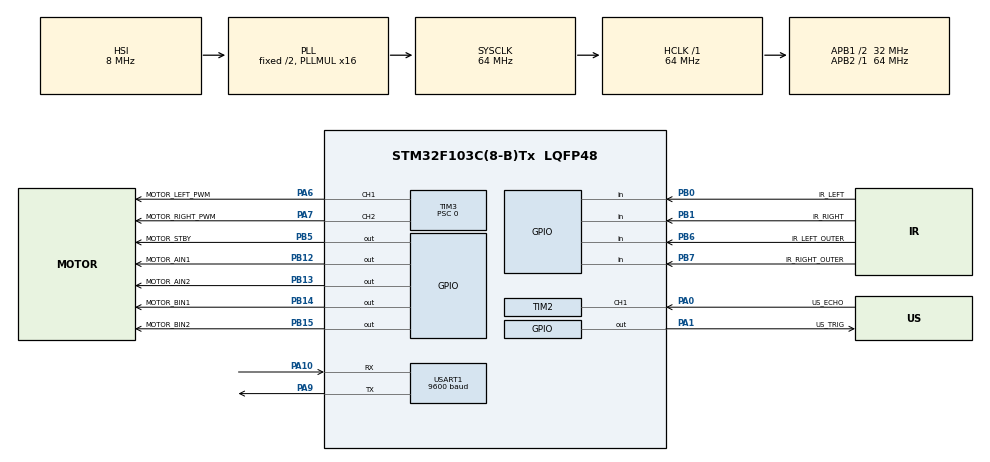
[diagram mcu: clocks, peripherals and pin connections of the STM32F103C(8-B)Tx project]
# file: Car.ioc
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Mcu.Family=STM32F1
Mcu.Name=STM32F103C(8-B)Tx
Mcu.Package=LQFP48
NVIC.PriorityGroup=NVIC_PRIORITYGROUP_4
NVIC.TIM2_IRQn=true\:1\:0\:false\:false\:true\:true\:true\:true
NVIC.USART1_IRQn=true\:2\:0\:false\:false\:true\:true\:true\:true
PA0-WKUP.GPIO_Label=US_ECHO
PA0-WKUP.Signal=S_TIM2_CH1_ETR
PA1.GPIO_Label=US_TRIG
PA1.GPIO_ModeDefaultOutputPP=GPIO_MODE_OUTPUT_PP
PA1.GPIO_PuPd=GPIO_NOPULL
PA1.GPIO_Speed=GPIO_SPEED_FREQ_LOW
PA1.PinState=GPIO_PIN_RESET
PA1.Signal=GPIO_Output
PA10.Mode=Asynchronous
PA10.Signal=USART1_RX
PA13.Mode=Serial_Wire
PA13.Signal=SYS_JTMS-SWDIO
PA14.Mode=Serial_Wire
PA14.Signal=SYS_JTCK-SWCLK
PA6.GPIO_Label=MOTOR_LEFT_PWM
PA6.Signal=S_TIM3_CH1
PA7.GPIO_Label=MOTOR_RIGHT_PWM
PA7.Signal=S_TIM3_CH2
PA9.Mode=Asynchronous
PA9.Signal=USART1_TX
PB0.GPIO_Label=IR_LEFT
PB0.GPIO_PuPd=GPIO_PULLUP
PB0.Signal=GPIO_Input
PB1.GPIO_Label=IR_RIGHT
PB1.GPIO_PuPd=GPIO_PULLUP
PB1.Signal=GPIO_Input
PB12.GPIO_Label=MOTOR_AIN1
PB12.GPIO_ModeDefaultOutputPP=GPIO_MODE_OUTPUT_PP
PB12.GPIO_PuPd=GPIO_NOPULL
PB12.GPIO_Speed=GPIO_SPEED_FREQ_LOW
PB12.PinState=GPIO_PIN_RESET
PB12.Signal=GPIO_Output
PB13.GPIO_Label=MOTOR_AIN2
PB13.GPIO_ModeDefaultOutputPP=GPIO_MODE_OUTPUT_PP
PB13.GPIO_PuPd=GPIO_NOPULL
PB13.GPIO_Speed=GPIO_SPEED_FREQ_LOW
PB13.PinState=GPIO_PIN_RESET
PB13.Signal=GPIO_Output
PB14.GPIO_Label=MOTOR_BIN1
PB14.GPIO_ModeDefaultOutputPP=GPIO_MODE_OUTPUT_PP
PB14.GPIO_PuPd=GPIO_NOPULL
PB14.GPIO_Speed=GPIO_SPEED_FREQ_LOW
PB14.PinState=GPIO_PIN_RESET
PB14.Signal=GPIO_Output
PB15.GPIO_Label=MOTOR_BIN2
PB15.GPIO_ModeDefaultOutputPP=GPIO_MODE_OUTPUT_PP
PB15.GPIO_PuPd=GPIO_NOPULL
PB15.GPIO_Speed=GPIO_SPEED_FREQ_LOW
PB15.PinState=GPIO_PIN_RESET
PB15.Signal=GPIO_Output
PB5.GPIO_Label=MOTOR_STBY
PB5.GPIO_ModeDefaultOutputPP=GPIO_MODE_OUTPUT_PP
PB5.GPIO_PuPd=GPIO_NOPULL
PB5.GPIO_Speed=GPIO_SPEED_FREQ_LOW
PB5.PinState=GPIO_PIN_RESET
PB5.Signal=GPIO_Output
PB6.GPIO_Label=IR_LEFT_OUTER
PB6.GPIO_PuPd=GPIO_PULLUP
PB6.Signal=GPIO_Input
PB7.GPIO_Label=IR_RIGHT_OUTER
PB7.GPIO_PuPd=GPIO_PULLUP
PB7.Signal=GPIO_Input
ProjectManager.HeapSize=0x200
ProjectManager.StackSize=0x400
ProjectManager.TargetToolchain=MDK-ARM V5
RCC.ADCPresc=RCC_ADCPCLK2_DIV8
RCC.AHBFreq_Value=64000000
RCC.APB1CLKDivider=RCC_HCLK_DIV2
RCC.APB1Freq_Value=32000000
RCC.APB1TimFreq_Value=64000000
RCC.APB2Freq_Value=64000000
RCC.APB2TimFreq_Value=64000000
RCC.HCLKFreq_Value=64000000
RCC.PLLMUL=RCC_PLL_MUL16
RCC.PLLSourceVirtual=RCC_PLLSOURCE_HSI_DIV2
RCC.SYSCLKFreq_VALUE=64000000
RCC.SYSCLKSource=RCC_SYSCLKSOURCE_PLLCLK
RCC.USBFreq_Value=64000000
SH.S_TIM2_CH1_ETR.0=TIM2_CH1,Input_Capture1_from_TI1
SH.S_TIM3_CH1.0=TIM3_CH1,PWM Generation1 CH1
SH.S_TIM3_CH2.0=TIM3_CH2,PWM Generation2 CH2
TIM2.Channel-Input_Capture1_from_TI1=TIM_CHANNEL_1
TIM2.ICFilter_CH1=0
TIM2.ICPolarity_CH1=TIM_INPUTCHANNELPOLARITY_RISING
TIM2.Period=65535
TIM2.Prescaler=63
TIM3.Channel-PWM\ Generation1\ CH1=TIM_CHANNEL_1
TIM3.Channel-PWM\ Generation2\ CH2=TIM_CHANNEL_2
TIM3.Period=3199
TIM3.Prescaler=0
TIM3.Pulse-PWM\ Generation1\ CH1=0
TIM3.Pulse-PWM\ Generation2\ CH2=0
USART1.BaudRate=9600
USART1.VirtualMode=VM_ASYNC
VP_TIM2_VS_ClockSourceINT.Mode=Internal
VP_TIM3_VS_ClockSourceINT.Mode=Internal
board=custom

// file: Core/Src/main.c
/* USER CODE BEGIN Header */
/**
  ******************************************************************************
  * @file           : main.c
  * @brief          : Main program body
  ******************************************************************************
  * @attention
  *
  * Copyright (c) 2026 STMicroelectronics.
  * All rights reserved.
  *
  * This software is licensed under terms that can be found in the LICENSE file
  * in the root directory of this software component.
  * If no LICENSE file comes with this software, it is provided AS-IS.
  *
  ******************************************************************************
  */
/* USER CODE END Header */
#include "main.h"
#include "tim.h"
#include "usart.h"
#include "gpio.h"

/* USER CODE BEGIN Includes */
#include "car_app.h"
/* USER CODE END Includes */

void SystemClock_Config(void);

int main(void)
{

  /* MCU Configuration--------------------------------------------------------*/

  /* Reset of all peripherals, Initializes the Flash interface and the Systick. */
  HAL_Init();

  /* Configure the system clock */
  SystemClock_Config();

  /* Initialize all configured peripherals */
  MX_GPIO_Init();
  MX_TIM2_Init();
  MX_TIM3_Init();
  MX_USART1_UART_Init();
  /* USER CODE BEGIN 2 */
  CarApp_Init();
  /* USER CODE END 2 */

  /* Infinite loop */
  while (1)
  {

    /* USER CODE BEGIN 3 */
    CarApp_Poll();
  }
  /* USER CODE END 3 */
}

void SystemClock_Config(void)
{
  RCC_OscInitTypeDef RCC_OscInitStruct = {0};
  RCC_ClkInitTypeDef RCC_ClkInitStruct = {0};

  /** Initializes the RCC Oscillators according to the specified parameters
  * in the RCC_OscInitTypeDef structure.
  */
  RCC_OscInitStruct.OscillatorType = RCC_OSCILLATORTYPE_HSI;
  RCC_OscInitStruct.HSIState = RCC_HSI_ON;
  RCC_OscInitStruct.HSICalibrationValue = RCC_HSICALIBRATION_DEFAULT;
  RCC_OscInitStruct.PLL.PLLState = RCC_PLL_ON;
  RCC_OscInitStruct.PLL.PLLSource = RCC_PLLSOURCE_HSI_DIV2;
  RCC_OscInitStruct.PLL.PLLMUL = RCC_PLL_MUL16;
  if (HAL_RCC_OscConfig(&RCC_OscInitStruct) != HAL_OK)
  {
    Error_Handler();
  }

  /** Initializes the CPU, AHB and APB buses clocks
  */
  RCC_ClkInitStruct.ClockType = RCC_CLOCKTYPE_HCLK|RCC_CLOCKTYPE_SYSCLK
                              |RCC_CLOCKTYPE_PCLK1|RCC_CLOCKTYPE_PCLK2;
  RCC_ClkInitStruct.SYSCLKSource = RCC_SYSCLKSOURCE_PLLCLK;
  RCC_ClkInitStruct.AHBCLKDivider = RCC_SYSCLK_DIV1;
  RCC_ClkInitStruct.APB1CLKDivider = RCC_HCLK_DIV2;
  RCC_ClkInitStruct.APB2CLKDivider = RCC_HCLK_DIV1;

  if (HAL_RCC_ClockConfig(&RCC_ClkInitStruct, FLASH_LATENCY_2) != HAL_OK)
  {
    Error_Handler();
  }
}

void Error_Handler(void)
{
  /* USER CODE BEGIN Error_Handler_Debug */
  CarApp_EmergencyStop();
  /* User can add his own implementation to report the HAL error return state */
  __disable_irq();
  while (1)
  {
  }
  /* USER CODE END Error_Handler_Debug */
}
